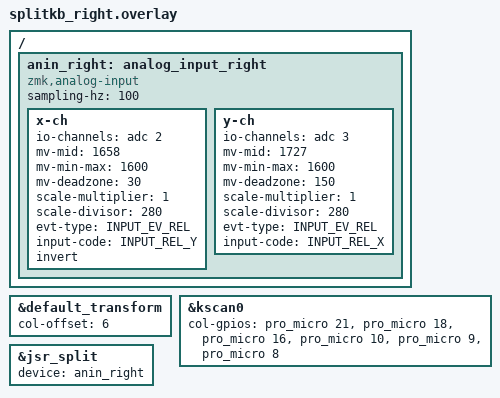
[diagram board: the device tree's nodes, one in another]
#include "splitkb.dtsi"

/* Lado direito: as colunas viram 6..11 no transform */
&default_transform {
    col-offset = <6>;
};

/* Colunas do lado DIREITO — ordem REVERSA (espelhado) */
&kscan0 {
    col-gpios
        = <&pro_micro 21 GPIO_ACTIVE_HIGH>
        , <&pro_micro 18 GPIO_ACTIVE_HIGH>
        , <&pro_micro 16 GPIO_ACTIVE_HIGH>
        , <&pro_micro 10 GPIO_ACTIVE_HIGH>
        , <&pro_micro 9  GPIO_ACTIVE_HIGH>
        , <&pro_micro 8  GPIO_ACTIVE_HIGH>
        ;
};

/ {
    /*
     * Joystick DIREITO (periférica). Alimenta o input-split -> vai pro central.
     * Papel: SCROLL fixo (definido no listener, no lado central).
     *
     * RECALIBRADO em 2026-07-21 (2a sessao, log bruto) com log bruto
     * (splitkb_right.conf temporario + snippet zmk-usb-logging).
     *   x-ch (AIN2, vira INPUT_REL_Y): centro 1658mV, desvio-padrao em
     *     repouso so 5.2mV -- estavel, quase igual a 1a calibracao (1661).
     *     Fio saudavel.
     *   y-ch (AIN3, vira INPUT_REL_X): centro 1727mV -- MUITO diferente da
     *     1a calibracao (1240mV, sessao anterior) e com desvio-padrao em
     *     repouso de 141.5mV (contra 5.2 do outro eixo). Isso NAO e deriva
     *     normal: e a assinatura de mau contato/fio solto na protoboard
     *     nesse fio especifico. Deadzone subiu de 30 pra 150 pra filtrar o
     *     ruido observado. SE O CENTRO VOLTAR A MUDAR numa proxima sessao,
     *     o fio desse canal precisa de reparo fisico (reencostar/soldar),
     *     recalibrar sozinho nao resolve um mau contato.
     */
    anin_right: analog_input_right {
        compatible = "zmk,analog-input";
        sampling-hz = <100>;

        x-ch {
            io-channels = <&adc 2>;
            mv-mid = <1658>;
            mv-min-max = <1600>;
            mv-deadzone = <30>;
            /* divisor 70 era calibrado pra CURSOR (pixel); scroll com o
             * mesmo numero fica disparado -- zip_xy_to_scroll_mapper so
             * renomeia o evento (X/Y -> wheel), nao reescala nada. */
            scale-multiplier = <1>;
            scale-divisor = <280>;
            evt-type = <INPUT_EV_REL>;
            input-code = <INPUT_REL_Y>;
            invert;                   /* cima<->baixo invertido (eixo vertical) */
        };
        y-ch {
            io-channels = <&adc 3>;
            mv-mid = <1727>;
            mv-min-max = <1600>;
            mv-deadzone = <150>;      /* subiu de 30: ruido de repouso deste
                                        * canal mede ~141mV (ver nota acima) */
            /* divisor 70 era calibrado pra CURSOR (pixel); scroll com o
             * mesmo numero fica disparado -- zip_xy_to_scroll_mapper so
             * renomeia o evento (X/Y -> wheel), nao reescala nada. */
            scale-multiplier = <1>;
            scale-divisor = <280>;
            evt-type = <INPUT_EV_REL>;
            input-code = <INPUT_REL_X>;
        };
    };
};

/* Conecta o joystick direito ao input-split reg=0 (lado periferico).
 * O no nasce disabled no common; aqui habilitamos e ligamos o device. */
&jsr_split {
    status = "okay";
    device = <&anin_right>;
};
